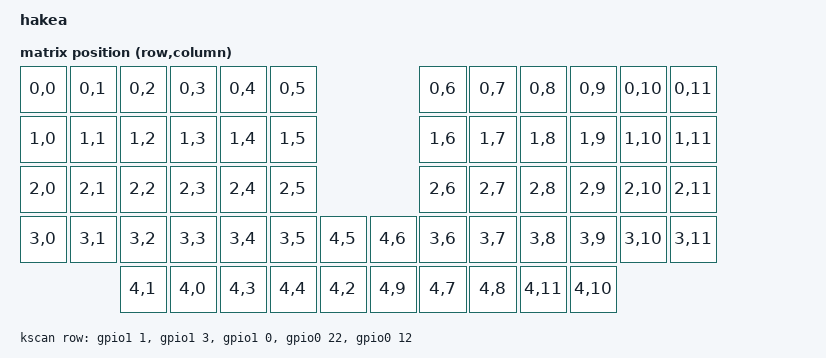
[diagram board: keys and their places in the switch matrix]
// This file was generated from a template. Edit it to match your keyboard.
// See https://docs.zephyrproject.org/3.5.0/hardware/porting/board_porting.html
// and https://zmk.dev/docs/development/hardware-integration/new-shield for more
// instructions.

/dts-v1/;
#include <nordic/nrf52840_qiaa.dtsi>
#include <dt-bindings/zmk/matrix_transform.h>

#include "hakea-layouts.dtsi"

/ {
    model = "hakea";
    compatible = "hakea";

    chosen {
        zephyr,code-partition = &code_partition;
        zephyr,console = &cdc_acm_uart;
        zephyr,sram = &sram0;
        zephyr,flash = &flash0;
        // Uncomment this if you enabled one of the "vddh" nodes below.
        zmk,battery = &vbatt;
        zmk,kscan = &kscan;
        zmk,matrix_transform = &default_transform;
        zmk,physical-layout = &default_layout;
    };

    kscan: kscan {
        compatible = "zmk,kscan-gpio-matrix";
        label = "KSCAN";
	    debounce-press-ms = <8>;
        debounce-release-ms = <8>;
        diode-direction = "col2row";
	
        row-gpios
            = <&gpio1 1 (GPIO_ACTIVE_HIGH | GPIO_PULL_DOWN)>
            , <&gpio1 3  (GPIO_ACTIVE_HIGH | GPIO_PULL_DOWN)>
            , <&gpio1 0  (GPIO_ACTIVE_HIGH | GPIO_PULL_DOWN)>
            , <&gpio0 22  (GPIO_ACTIVE_HIGH | GPIO_PULL_DOWN)>
            , <&gpio0 12  (GPIO_ACTIVE_HIGH | GPIO_PULL_DOWN)>
            ;

    };

    default_transform: keymap_transform_0 {
        compatible = "zmk,matrix-transform";
        columns = <12>;
        rows = <5>;
// | SW6  | SW5  | SW4  | SW3  | SW2  | SW1  |                 | SW1  | SW2  | SW3  | SW4  | SW5  | SW6  |
// | SW12 | SW11 | SW10 | SW9  | SW8  | SW7  |                 | SW7  | SW8  | SW9  | SW10 | SW11 | SW12 |
// | SW18 | SW17 | SW16 | SW15 | SW14 | SW13 |                 | SW13 | SW14 | SW15 | SW16 | SW17 | SW18 |
// | SW24 | SW23 | SW22 | SW21 | SW20 | SW19 | SW25 |   | SW25 | SW19 | SW20 | SW21 | SW22 | SW23 | SW24 |
//               | SW30 | SW29 | SW28 | SW27 | SW26 |   | SW26 | SW27 | SW28 | SW29 | SW30 |
        map = <
RC(0,0) RC(0,1) RC(0,2) RC(0,3) RC(0,4) RC(0,5)                 RC(0,6) RC(0,7) RC(0,8)  RC(0,9) RC(0,10) RC(0,11)
RC(1,0) RC(1,1) RC(1,2) RC(1,3) RC(1,4) RC(1,5)                 RC(1,6) RC(1,7) RC(1,8)  RC(1,9) RC(1,10) RC(1,11)
RC(2,0) RC(2,1) RC(2,2) RC(2,3) RC(2,4) RC(2,5)                 RC(2,6) RC(2,7) RC(2,8)  RC(2,9) RC(2,10) RC(2,11)
RC(3,0) RC(3,1) RC(3,2) RC(3,3) RC(3,4) RC(3,5) RC(4,5) RC(4,6) RC(3,6) RC(3,7) RC(3,8)  RC(3,9) RC(3,10) RC(3,11)
                RC(4,1) RC(4,0) RC(4,3) RC(4,4) RC(4,2) RC(4,9) RC(4,7) RC(4,8) RC(4,11) RC(4,10)
        >;
    };

    leds {
        compatible = "gpio-leds";

        // If you have a GPIO routed to a status LED, set it here.
        // Otherwise, delete this block.
        blue_led: led_0 {
            gpios = <&gpio0 0 GPIO_ACTIVE_HIGH>;
        };
    };    

    vbatt: vbatt {
  		compatible = "zmk,battery-voltage-divider";
  		io-channels = <&adc 2>; // could be adc 1
  		output-ohms = <2000000>;
  		full-ohms = <(2000000 + 806000)>;
  	};
};

&adc {
    status = "okay";
};

&gpiote {
    status = "okay";
};

&gpio0 {
    status = "okay";
};

&gpio1 {
    status = "okay";
};

&uart0 {
    compatible = "nordic,nrf-uarte";
    current-speed = <115200>;
    pinctrl-0 = <&uart0_default>;
    pinctrl-1 = <&uart0_sleep>;
    pinctrl-names = "default", "sleep";
};

zephyr_udc0: &usbd {
    status = "okay";
};

&flash0 {
    // Adjust this flash map as is necessary for your board. For more information, see
    // https://docs.zephyrproject.org/3.5.0/services/storage/flash_map/flash_map.html#relationship-with-devicetree
    partitions {
        compatible = "fixed-partitions";
        #address-cells = <1>;
        #size-cells = <1>;

        code_partition: partition@1000 {
            reg = <DT_SIZE_K(4) DT_SIZE_K(844)>;
        };

        // If using a bootloader with SoftDevice included, replace the code_partition
        // node above with the following. If using SoftDevice v7, change 26000 to 27000.

        // sd_partition: partition@0 {
        //     reg = <0x0 <DT_SIZE_K(4)>;
        // };
        // code_partition: partition@26000 {
        //     reg = <DT_SIZE_K(152) DT_SIZE_K(792)>;
        // };

        // The flash starting at 0x000d4000 and ending at
        // 0x000f3fff is reserved for use by the application.

        // Storage partition will be used by NVS if enabled.
        storage_partition: partition@d4000 {
            reg = <DT_SIZE_K(848) DT_SIZE_K(128)>;
        };

        boot_partition: partition@f4000 {
            reg = <DT_SIZE_K(976) DT_SIZE_K(48)>;
        };
    };
};
